AUTOSAR XML (schema 4-3-0)
package /App_Repro
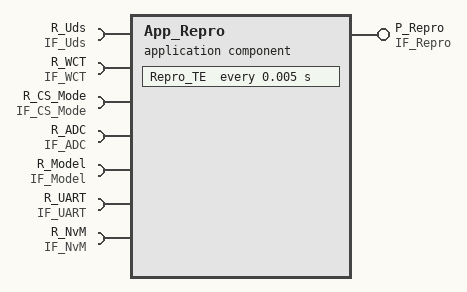
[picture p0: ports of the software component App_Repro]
  application sw component type App_Repro
    provide port P_Repro: nonqueued-sender-com-spec=Repro_STR, provided-interface=IF_Repro
    7 x require port:
      R_Uds: nonqueued-receiver-com-spec=Uds_STR, required-interface=IF_Uds
      R_WCT: nonqueued-receiver-com-spec=WCT_STR, required-interface=IF_WCT
      R_CS_Mode: required-com-specs=[ModeInit, NvMInit, ApplicationInit], required-interface=IF_CS_Mode
      R_ADC: nonqueued-receiver-com-spec=ADC_STR, required-interface=IF_ADC
      R_Model: nonqueued-receiver-com-spec=Model_STR, required-interface=IF_Model
      R_UART: nonqueued-receiver-com-spec=UART_STR, required-interface=IF_UART
      R_NvM: nonqueued-receiver-com-spec=NvM_STR, required-interface=IF_NvM
    behavior InternalBehavior: data-type-mapping=DataTypeMappingSet_WPC
      timing event TE_Repro_TE: start-on-event=Repro_TE, period=0.005
      runnable Repro_TE: symbol=Repro_TE_Runnable
        data-receive-point-by-arguments:
          6 x access, all with scope=COMMUNICATION-INTER-ECU:
            DRPBA_Repro_TE_R_ADC_Structure: accessed-variable=R_ADC.ADC_STR
            DRPBA_Repro_TE_R_Model_Structure: accessed-variable=R_Model.Model_STR
            DRPBA_Repro_TE_R_UART_Structure: accessed-variable=R_UART.UART_STR
            DRPBA_Repro_TE_R_WCT_WCT_STR_ALL: accessed-variable=R_WCT.WCT_STR
            DRPBA_Repro_TE_R_Uds_Uds_STR: accessed-variable=R_Uds.Uds_STR
            DRPBA_Repro_TE_R_NvM_NvM_STR: accessed-variable=R_NvM.NvM_STR
        data-send-points:
          access DSP_Repro_TE_P_Repro_Structure: accessed-variable=P_Repro.Repro_STR, scope=COMMUNICATION-INTER-ECU
        sync call SSCP_Repro_TE_R_CS_Mode_ApplicationInit: operation=R_CS_Mode.ApplicationInit
        sync call SSCP_Repro_TE_R_CS_Mode_ModeInit: operation=R_CS_Mode.ModeInit
        sync call SSCP_Repro_TE_R_CS_Mode_NvMInit: operation=R_CS_Mode.NvMInit
  sender receiver interface IF_Repro  # NFC SWC Output
    data Repro_STR: type=IDT_Repro_STR
